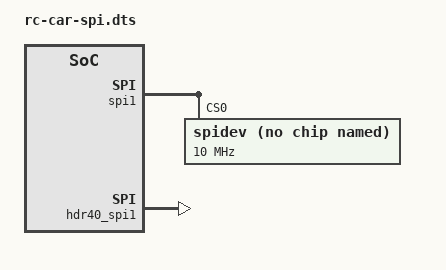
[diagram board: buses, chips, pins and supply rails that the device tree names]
/dts-v1/;
/plugin/;

/ {
    compatible = "nvidia,jetson-nano";

    fragment@0 {
        target = <&spi1>;
        __overlay__ {
            status = "okay";
        };
    };

    fragment@1 {
        target = <&hdr40_spi1>;
        __overlay__ {
            status = "okay";
        };
    };

    fragment@2 {
        target = <&spi1>;
        __overlay__ {
            spidev@0 {
                compatible = "spidev";
                reg = <0>;
                spi-max-frequency = <10000000>;
                status = "okay";
            };
        };
    };
};
